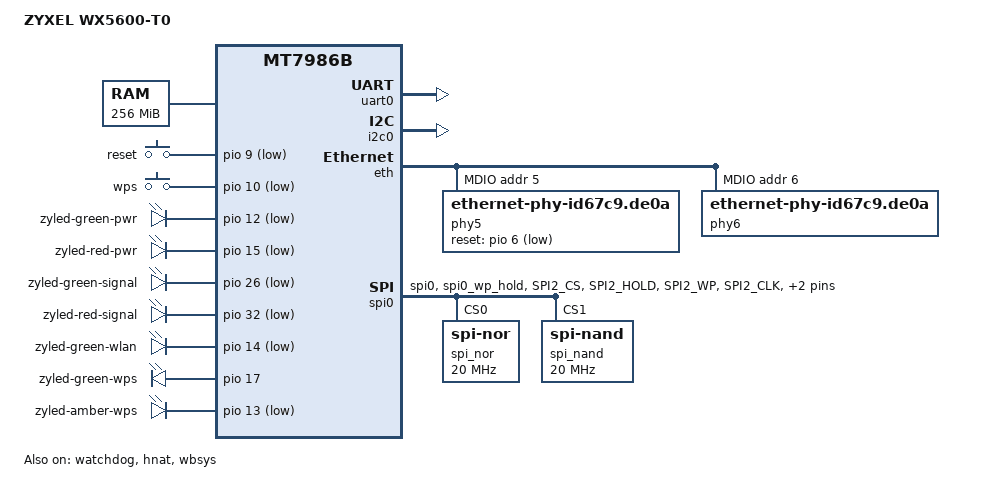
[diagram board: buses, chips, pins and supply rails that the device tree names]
/dts-v1/;
#include "mt7986b.dtsi"
#include "mt7986b-pinctrl.dtsi"
#include "mt7986-spim-nand-512M-256kB-partition.dtsi"
#include <dt-bindings/input/input.h>
#include <dt-bindings/gpio/gpio.h>
/ {
	model = "ZYXEL WX5600-T0";
	compatible = "mediatek,mt7986b-spim-snand-wx5600-t0-c2-2";
	chosen {
		bootargs = "console=ttyS0,115200n1 loglevel=8  \
				earlycon=uart8250,mmio32,0x11002000";
	};

	memory {
		reg = <0 0x40000000 0 0x10000000>;
	};

	gpio-keys {
		compatible = "gpio-keys";
		poll-interval = <20>;

		reset-button {
			label = "reset";
			gpios = <&pio 9 1>;
			linux,code = <KEY_RESTART>;
		};
		wps-button {
			label = "wps";
			gpios = <&pio 10 1>;
			linux,code = <KEY_WPS_BUTTON>;
		};
	};

	zyleds {
		compatible = "gpio-leds";

		led_green_pwr {
			label = "zyled-green-pwr";
			gpios = <&pio 12 GPIO_ACTIVE_LOW>;
			linux,default-trigger = "timer"; /* Default blinking */
			led-pattern = <125 125>; /* Fast blink is 4 HZ */
		};

		led_red_pwr {
			label = "zyled-red-pwr";
			gpios = <&pio 15 GPIO_ACTIVE_LOW>;
			default-state = "off";
		};

		led_green_signal {
			label = "zyled-green-signal";
			gpios = <&pio 26 GPIO_ACTIVE_LOW>;
			default-state = "off";
		};

		led_red_signal {
			label = "zyled-red-signal";
			gpios = <&pio 32 GPIO_ACTIVE_LOW>;
			default-state = "off";
		};

		led_green_wlan {
			label = "zyled-green-wlan";
			gpios = <&pio 14 GPIO_ACTIVE_LOW>;
			default-state = "off";
		};

		led_green_wps {
			label = "zyled-green-wps";
			gpios = <&pio 17 GPIO_ACTIVE_HIGH>;
			default-state = "off";
		};

		led_red_wps {
			label = "zyled-amber-wps";
			gpios = <&pio 13 GPIO_ACTIVE_LOW>;
			default-state = "off";
		};

	};

};

&uart0 {
	status = "okay";
};

/* Warning: pins shared with &snand */
&uart1 {
	pinctrl-names = "default";
	pinctrl-0 = <&uart1_pins>;
	status = "disabled";
};

/* Warning: pins shared with &spi1 */
&uart2 {
	pinctrl-names = "default";
	pinctrl-0 = <&uart2_pins>;
	status = "disabled";
};

&i2c0 {
	pinctrl-names = "default";
	pinctrl-0 = <&i2c_pins>;
	status = "okay";
};

&watchdog {
	status = "okay";
};

&eth {
	status = "okay";

	gmac0: mac@0 {
		compatible = "mediatek,eth-mac";
		reg = <0>;
		phy-mode = "2500base-x";

		fixed-link {
			speed = <2500>;
			full-duplex;
			pause;
		};
	};

	gmac1: mac@1 {
		compatible = "mediatek,eth-mac";
		reg = <1>;
		phy-mode = "2500base-x";

		fixed-link {
			speed = <2500>;
			full-duplex;
			pause;
		};
	};

	mdio: mdio-bus {
		#address-cells = <1>;
		#size-cells = <0>;

		phy5: phy@5 {
			compatible = "ethernet-phy-id67c9.de0a";
			reg = <5>;
			reset-gpios = <&pio 6 1>;
			reset-assert-us = <50000>;
			reset-deassert-us = <20000>;
			phy-mode = "2500base-x";
			maxlinear,led-reg = <1008 0 0 0>; /* enable led0 for all link/act, and disable led1~3 */
			ifname = "eth1";
		};

		phy6: phy@6 {
			compatible = "ethernet-phy-id67c9.de0a";
			reg = <6>;
			phy-mode = "2500base-x";
			maxlinear,led-reg = <1008 0 0 0>; /* enable led0 for all link/act, and disable led1~3 */
			ifname = "eth0";
		};

	};
};

&hnat {
	mtketh-wan = "eth1";
	mtketh-lan = "eth0";
	mtketh-max-gmac = <2>;
	status = "okay";
};

&spi0 {
	pinctrl-names = "default";
	pinctrl-0 = <&spi_flash_pins>;
	cs-gpios = <0>, <0>;
	status = "okay";

	spi_nor@0 {
		#address-cells = <1>;
		#size-cells = <1>;
		compatible = "jedec,spi-nor";
		reg = <0>;
		spi-max-frequency = <20000000>;
		spi-tx-buswidth = <4>;
		spi-rx-buswidth = <4>;
	};

	spi_nand: spi_nand@1 {
		#address-cells = <1>;
		#size-cells = <1>;
		compatible = "spi-nand";
		reg = <1>;
		spi-max-frequency = <20000000>;
		spi-tx-buswidth = <4>;
		spi-rx-buswidth = <4>;
	};
};

/* Warning: pins shared with &uart2 */
&spi1 {
	pinctrl-names = "default";
	pinctrl-0 = <&spic_pins>;
	status = "disabled";
};

&wbsys {
	mediatek,mtd-eeprom = <&factory 0x0000>;
	status = "okay";
	pinctrl-names = "default", "dbdc";
	pinctrl-0 = <&wf_2g_5g_pins>;
	pinctrl-1 = <&wf_dbdc_pins>;
};

&pio {
	spi_flash_pins: spi-flash-pins-33-to-38 {
		mux {
			function = "flash";
			groups = "spi0", "spi0_wp_hold";
		};
		conf-pu {
			pins = "SPI2_CS", "SPI2_HOLD", "SPI2_WP";
			drive-strength = <MTK_DRIVE_8mA>;
			mediatek,pull-up-adv = <0>;	/* bias-disable */
		};
		conf-pd {
			pins = "SPI2_CLK", "SPI2_MOSI", "SPI2_MISO";
			drive-strength = <MTK_DRIVE_8mA>;
			mediatek,pull-down-adv = <0>;	/* bias-disable */
		};

	};

	wf_2g_5g_pins: wf_2g_5g-pins {
		mux {
			function = "wifi";
			groups = "wf_2g", "wf_5g";
		};
		conf {
			pins = "WF0_HB1", "WF0_HB2", "WF0_HB3", "WF0_HB4",
			       "WF0_HB0", "WF0_HB0_B", "WF0_HB5", "WF0_HB6",
			       "WF0_HB7", "WF0_HB8", "WF0_HB9", "WF0_HB10",
			       "WF0_TOP_CLK", "WF0_TOP_DATA", "WF1_HB1",
			       "WF1_HB2", "WF1_HB3", "WF1_HB4", "WF1_HB0",
			       "WF1_HB5", "WF1_HB6", "WF1_HB7", "WF1_HB8",
			       "WF1_TOP_CLK", "WF1_TOP_DATA";
			drive-strength = <MTK_DRIVE_4mA>;
		};
	};

	wf_dbdc_pins: wf_dbdc-pins {
		mux {
			function = "wifi";
			groups = "wf_dbdc";
		};
		conf {
			pins = "WF0_HB1", "WF0_HB2", "WF0_HB3", "WF0_HB4",
			       "WF0_HB0", "WF0_HB0_B", "WF0_HB5", "WF0_HB6",
			       "WF0_HB7", "WF0_HB8", "WF0_HB9", "WF0_HB10",
			       "WF0_TOP_CLK", "WF0_TOP_DATA", "WF1_HB1",
			       "WF1_HB2", "WF1_HB3", "WF1_HB4", "WF1_HB0",
			       "WF1_HB5", "WF1_HB6", "WF1_HB7", "WF1_HB8",
			       "WF1_TOP_CLK", "WF1_TOP_DATA";
			drive-strength = <MTK_DRIVE_4mA>;
		};
	};
};
